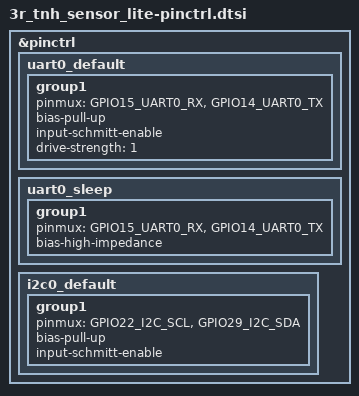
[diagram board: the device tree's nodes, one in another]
/*
 * Copyright (c) 2026 MASSDRIVER EI (massdriver.space)
 * SPDX-License-Identifier: Apache-2.0
 */

#include <dt-bindings/pinctrl/bl704lx-pinctrl.h>

&pinctrl {
	uart0_default: uart0_default {
		group1 {
			pinmux = <GPIO15_UART0_RX>,
				 <GPIO14_UART0_TX>;
			bias-pull-up;
			input-schmitt-enable;
			drive-strength = <1>;
		};
	};

	uart0_sleep: uart0_sleep {
		group1 {
			pinmux = <GPIO15_UART0_RX>,
				 <GPIO14_UART0_TX>;
			bias-high-impedance;
		};
	};

	i2c0_default: i2c0_default {
		group1 {
			pinmux = <GPIO22_I2C_SCL>,
				 <GPIO29_I2C_SDA>;
			bias-pull-up;
			input-schmitt-enable;
		};
	};
};
